AUTOSAR XML (schema 321)
standard types defined: Boolean, UInt16, UInt8, Float
package /ComponentType
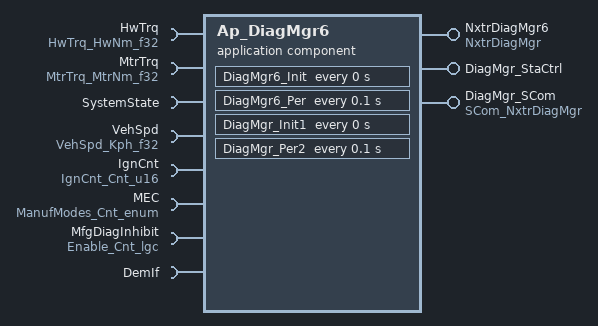
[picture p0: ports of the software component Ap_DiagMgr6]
  application software component type Ap_DiagMgr6
    provide port NxtrDiagMgr6: provided-interface=NxtrDiagMgr
      provided-com-specs:
        operation=GetNTCFailed, queue-length=1
        operation=GetNTCActive, queue-length=1
        operation=GetNTCStatus, queue-length=1
        operation=SetNTCStatus, queue-length=1
    8 x require port:
      HwTrq: unqueued-receiver-com-spec{data-element=HwNm_f32, handle-invalid=DONT-INVALIDATE, init-value=D_ZERO_ULS_F32}, required-interface=HwTrq_HwNm_f32
      MtrTrq: unqueued-receiver-com-spec{data-element=MtrNm_f32, init-value=D_ZERO_ULS_F32}, required-interface=MtrTrq_MtrNm_f32
      SystemState: required-interface=SystemState
      VehSpd: unqueued-receiver-com-spec{data-element=Kph_f32, handle-invalid=DONT-INVALIDATE, init-value=D_ZERO_ULS_F32}, required-interface=VehSpd_Kph_f32
      IgnCnt: unqueued-receiver-com-spec{data-element=Cnt_u16, init-value=D_ZERO_CNT_U16}, required-interface=IgnCnt_Cnt_u16
      MEC: unqueued-receiver-com-spec{data-element=Cnt_enum, handle-invalid=DONT-INVALIDATE, init-value=D_MANUFMODEINIT_CNT_ENUM}, required-interface=ManufModes_Cnt_enum
      MfgDiagInhibit: unqueued-receiver-com-spec{data-element=Enable_Cnt_lgc/Cnt_lgc, handle-invalid=DONT-INVALIDATE, init-value=D_FALSE_CNT_LGC}, required-interface=Enable_Cnt_lgc
      DemIf: required-com-specs=[DemShutdown, RestartDem, SetEventStatus, SetOperationCycleState], required-interface=DemIf
    provide port DiagMgr_StaCtrl: server-com-spec=Shutdown, provided-interface=DiagMgr_StaCtrl
    provide port DiagMgr_SCom: provided-interface=SCom_NxtrDiagMgr
      provided-com-specs:
        operation=GetNTCInfo, queue-length=1
        operation=ReadStrgArray, queue-length=1
        operation=ResetNTCStatus, queue-length=1
        operation=ClearBlackBox, queue-length=1
        operation=ClearLatchCounters, queue-length=1
  internal behavior Ap_DiagMgr6_InternalBehavior: component=Ap_DiagMgr6
    timing event DiagMgr6_Init_InitEvent: start-on-event=DiagMgr6_Init, period=0
    timing event TMT_DiagMgr6_Per: start-on-event=DiagMgr6_Per, period=0.1
    mode switch event MST_DiagMgr6_Trns_0: start-on-event=DiagMgr6_Trns, activation=EXIT, mode=SystemState.Mode.OFF
    timing event DiagMgr_Init1_InitEvent: start-on-event=DiagMgr_Init1, period=0
    timing event TMT_DiagMgr_Per2: mode-dependency=dependent-on-mode=SystemState.Mode.OFF, start-on-event=DiagMgr_Per2, period=0.1
    6 x operation invoked event:
      OIT_DiagMgr_SCom_GetNTCInfo_DiagMgr_SCom_GetInfo: start-on-event=DiagMgr_SCom_GetNTCInfo, operation=DiagMgr_SCom.GetNTCInfo
      OIT_DiagMgr_StaCtrl_Shutdown_DiagMgr_StaCtrl_Shutdown: start-on-event=DiagMgr_StaCtrl_Shutdown, operation=DiagMgr_StaCtrl.Shutdown
      OIT_DiagMgr_SCom_ReadStrgArray_DiagMgr_SCom_ReadStrgArray: start-on-event=DiagMgr_SCom_ReadStrgArray, operation=DiagMgr_SCom.ReadStrgArray
      OIT_DiagMgr_SCom_ReadStrgArray_DiagMgr_SCom_ResetNTCStatus: start-on-event=DiagMgr_SCom_ResetNTCStatus, operation=DiagMgr_SCom.ResetNTCStatus
      OIT_DiagMgr_SCom_ReadStrgArray_DiagMgr_SCom_ClearBlackBox: start-on-event=DiagMgr_SCom_ClearBlackBox, operation=DiagMgr_SCom.ClearBlackBox
      OIT_DiagMgr_SCom_ReadStrgArray_DiagMgr_SCom_ClearLatchCounters: start-on-event=DiagMgr_SCom_ClearLatchCounters, operation=DiagMgr_SCom.ClearLatchCounters
    mode switch event MST_DiagMgr_Trns1_0: start-on-event=DiagMgr_Trns1, activation=EXIT, mode=SystemState.Mode.OFF
    4 x operation invoked event:
      OIT_NxtrDiagMgr6_GetNTCFailed_NxtrDiagMgr6_GetNTCFailed: start-on-event=NxtrDiagMgr6_GetNTCFailed, operation=NxtrDiagMgr6.GetNTCFailed
      OIT_NxtrDiagMgr6_GetNTCActive_NxtrDiagMgr6_GetNTCActive: start-on-event=NxtrDiagMgr6_GetNTCActive, operation=NxtrDiagMgr6.GetNTCActive
      OIT_NxtrDiagMgr6_GetNTCStatus_NxtrDiagMgr6_GetNTCStatus: start-on-event=NxtrDiagMgr6_GetNTCStatus, operation=NxtrDiagMgr6.GetNTCStatus
      OIT_NxtrDiagMgr6_SetNTCStatus_NxtrDiagMgr6_SetNTCStatus: start-on-event=NxtrDiagMgr6_SetNTCStatus, operation=NxtrDiagMgr6.SetNTCStatus
    port-api-options:
      enable-take-address=false, indirect-api=false, port=NxtrDiagMgr6
      enable-take-address=false, indirect-api=false, port=Ap_DiagMgr6/MEC
      enable-take-address=false, indirect-api=false, port=Ap_DiagMgr6/MfgDiagInhibit
      enable-take-address=false, indirect-api=false, port=DemIf
      enable-take-address=false, indirect-api=false, port=DiagMgr_SCom
      enable-take-address=false, indirect-api=false, port=DemIf
    16 x runnable:
      NxtrDiagMgr6_GetNTCFailed: can-be-invoked-concurrently=true
      NxtrDiagMgr6_GetNTCActive: can-be-invoked-concurrently=true
      NxtrDiagMgr6_GetNTCStatus: can-be-invoked-concurrently=true
      NxtrDiagMgr6_SetNTCStatus: can-be-invoked-concurrently=true
        6 x data receive point:
          REC_MEC_Cnt_enum: data-element=MEC.Cnt_enum
          REC_MfgDiagInhibit_Cnt_lgc: data-element=MfgDiagInhibit.Cnt_lgc
          REC_HwTrq_HwNm_f32: data-element=HwTrq.HwNm_f32
          REC_MtrTrq_MtrNm_f32: data-element=MtrTrq.MtrNm_f32
          REC_IgnCnt_Cnt_u16: data-element=IgnCnt.Cnt_u16
          REC_VehSpd_Kph_f32: data-element=VehSpd.Kph_f32
      DiagMgr6_Init
        sync call SC_DemIf_SetOperationCycleState: operation=DemIf.SetOperationCycleState, timeout=0
      DiagMgr_StaCtrl_Shutdown
        sync call SC_DemIf_DemShutdown: operation=DemIf.DemShutdown, timeout=0
      DiagMgr6_Per
      DiagMgr6_Trns
      DiagMgr_Init1
      DiagMgr_Per2
        sync call SC_DemIf_SetEventStatus: operation=DemIf.SetEventStatus, timeout=0
      DiagMgr_Trns1
        sync call SC_DemIf_RestartDem: operation=DemIf.RestartDem, timeout=0
        sync call SC_DemIf_SetOperationCycleState: operation=DemIf.SetOperationCycleState, timeout=0
      DiagMgr_SCom_GetNTCInfo
      DiagMgr_SCom_ReadStrgArray
      DiagMgr_SCom_ResetNTCStatus
      DiagMgr_SCom_ClearBlackBox
      DiagMgr_SCom_ClearLatchCounters
  swc implementation DiagMgr6_Implementation: behavior=Ap_DiagMgr6_InternalBehavior
    code-descriptors:
      code Code: type=SRC
package /ComponentType
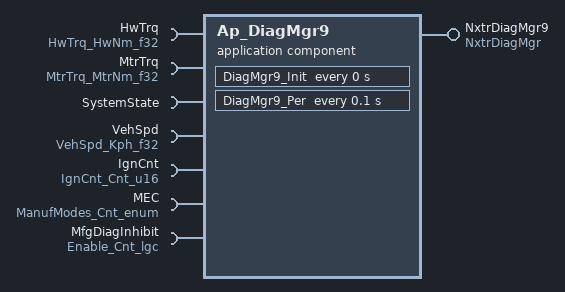
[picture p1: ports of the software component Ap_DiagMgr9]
  application software component type Ap_DiagMgr9
    provide port NxtrDiagMgr9: provided-interface=NxtrDiagMgr
      provided-com-specs:
        operation=GetNTCFailed, queue-length=1
        operation=GetNTCActive, queue-length=1
        operation=GetNTCStatus, queue-length=1
        operation=SetNTCStatus, queue-length=1
    7 x require port:
      HwTrq: unqueued-receiver-com-spec{data-element=HwNm_f32, handle-invalid=DONT-INVALIDATE, init-value=D_ZERO_ULS_F32}, required-interface=HwTrq_HwNm_f32
      MtrTrq: unqueued-receiver-com-spec{data-element=MtrNm_f32, init-value=D_ZERO_ULS_F32}, required-interface=MtrTrq_MtrNm_f32
      SystemState: required-interface=SystemState
      VehSpd: unqueued-receiver-com-spec{data-element=Kph_f32, handle-invalid=DONT-INVALIDATE, init-value=D_ZERO_ULS_F32}, required-interface=VehSpd_Kph_f32
      IgnCnt: unqueued-receiver-com-spec{data-element=Cnt_u16, init-value=D_ZERO_CNT_U16}, required-interface=IgnCnt_Cnt_u16
      MEC: unqueued-receiver-com-spec{data-element=Cnt_enum, handle-invalid=DONT-INVALIDATE, init-value=D_MANUFMODEINIT_CNT_ENUM}, required-interface=ManufModes_Cnt_enum
      MfgDiagInhibit: unqueued-receiver-com-spec{data-element=Enable_Cnt_lgc/Cnt_lgc, handle-invalid=DONT-INVALIDATE, init-value=D_FALSE_CNT_LGC}, required-interface=Enable_Cnt_lgc
  internal behavior Ap_DiagMgr9_InternalBehavior: component=Ap_DiagMgr9
    timing event DiagMgr9_Init_InitEvent: start-on-event=DiagMgr9_Init, period=0
    timing event TMT_DiagMgr9_Per: start-on-event=DiagMgr9_Per, period=0.1
    mode switch event MST_DiagMgr9_Trns_0: start-on-event=DiagMgr9_Trns, activation=EXIT, mode=SystemState.Mode.OFF
    4 x operation invoked event:
      OIT_NxtrDiagMgr9_GetNTCFailed_NxtrDiagMgr9_GetNTCFailed: start-on-event=NxtrDiagMgr9_GetNTCFailed, operation=NxtrDiagMgr9.GetNTCFailed
      OIT_NxtrDiagMgr9_GetNTCActive_NxtrDiagMgr9_GetNTCActive: start-on-event=NxtrDiagMgr9_GetNTCActive, operation=NxtrDiagMgr9.GetNTCActive
      OIT_NxtrDiagMgr9_GetNTCStatus_NxtrDiagMgr9_GetNTCStatus: start-on-event=NxtrDiagMgr9_GetNTCStatus, operation=NxtrDiagMgr9.GetNTCStatus
      OIT_NxtrDiagMgr9_SetNTCStatus_NxtrDiagMgr9_SetNTCStatus: start-on-event=NxtrDiagMgr9_SetNTCStatus, operation=NxtrDiagMgr9.SetNTCStatus
    port-api-options:
      enable-take-address=false, indirect-api=false, port=NxtrDiagMgr9
      enable-take-address=false, indirect-api=false, port=Ap_DiagMgr9/MEC
      enable-take-address=false, indirect-api=false, port=Ap_DiagMgr9/MfgDiagInhibit
    7 x runnable:
      NxtrDiagMgr9_GetNTCFailed: can-be-invoked-concurrently=true
      NxtrDiagMgr9_GetNTCActive: can-be-invoked-concurrently=true
      NxtrDiagMgr9_GetNTCStatus: can-be-invoked-concurrently=true
      NxtrDiagMgr9_SetNTCStatus: can-be-invoked-concurrently=true
        6 x data receive point:
          REC_MEC_Cnt_enum: data-element=MEC.Cnt_enum
          REC_MfgDiagInhibit_Cnt_lgc: data-element=MfgDiagInhibit.Cnt_lgc
          REC_HwTrq_HwNm_f32: data-element=HwTrq.HwNm_f32
          REC_MtrTrq_MtrNm_f32: data-element=MtrTrq.MtrNm_f32
          REC_IgnCnt_Cnt_u16: data-element=IgnCnt.Cnt_u16
          REC_VehSpd_Kph_f32: data-element=VehSpd.Kph_f32
      DiagMgr9_Init
      DiagMgr9_Per
      DiagMgr9_Trns
  swc implementation DiagMgr9_Implementation: behavior=Ap_DiagMgr9_InternalBehavior
    code-descriptors:
      code Code: type=SRC
package /ComponentType
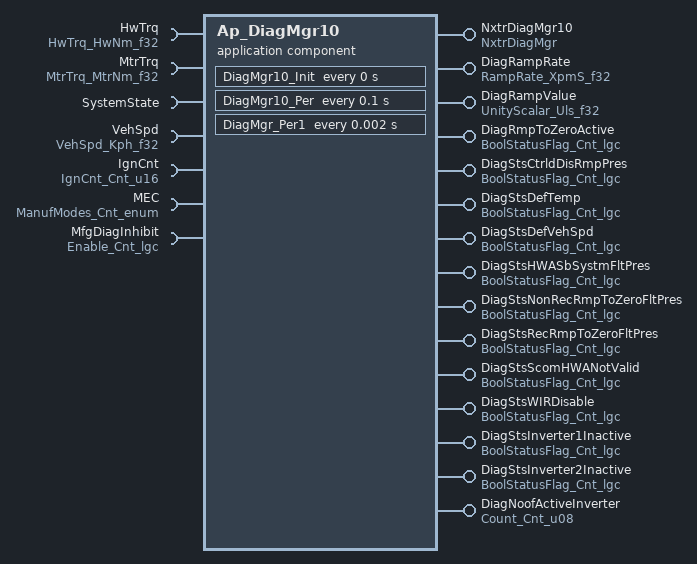
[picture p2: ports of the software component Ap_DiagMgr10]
  application software component type Ap_DiagMgr10
    provide port NxtrDiagMgr10: provided-interface=NxtrDiagMgr
      provided-com-specs:
        operation=GetNTCFailed, queue-length=1
        operation=GetNTCActive, queue-length=1
        operation=GetNTCStatus, queue-length=1
        operation=SetNTCStatus, queue-length=1
    7 x require port:
      HwTrq: unqueued-receiver-com-spec{data-element=HwNm_f32, handle-invalid=DONT-INVALIDATE, init-value=D_ZERO_ULS_F32}, required-interface=HwTrq_HwNm_f32
      MtrTrq: unqueued-receiver-com-spec{data-element=MtrNm_f32, init-value=D_ZERO_ULS_F32}, required-interface=MtrTrq_MtrNm_f32
      SystemState: required-interface=SystemState
      VehSpd: unqueued-receiver-com-spec{data-element=Kph_f32, handle-invalid=DONT-INVALIDATE, init-value=D_ZERO_ULS_F32}, required-interface=VehSpd_Kph_f32
      IgnCnt: unqueued-receiver-com-spec{data-element=Cnt_u16, init-value=D_ZERO_CNT_U16}, required-interface=IgnCnt_Cnt_u16
      MEC: unqueued-receiver-com-spec{data-element=Cnt_enum, handle-invalid=DONT-INVALIDATE, init-value=D_MANUFMODEINIT_CNT_ENUM}, required-interface=ManufModes_Cnt_enum
      MfgDiagInhibit: unqueued-receiver-com-spec{data-element=Enable_Cnt_lgc/Cnt_lgc, handle-invalid=DONT-INVALIDATE, init-value=D_FALSE_CNT_LGC}, required-interface=Enable_Cnt_lgc
    14 x provide port:
      DiagRampRate: unqueued-sender-com-spec{data-element=XpmS_f32, can-invalidate=false, init-value=D_ZERO_ULS_F32}, provided-interface=RampRate_XpmS_f32
      DiagRampValue: unqueued-sender-com-spec{data-element=Uls_f32, can-invalidate=false, init-value=D_ZERO_ULS_F32}, provided-interface=UnityScalar_Uls_f32
      DiagRmpToZeroActive: unqueued-sender-com-spec{data-element=BoolStatusFlag_Cnt_lgc/Cnt_lgc, can-invalidate=false, init-value=D_FALSE_CNT_LGC}, provided-interface=BoolStatusFlag_Cnt_lgc
      DiagStsCtrldDisRmpPres: unqueued-sender-com-spec{data-element=BoolStatusFlag_Cnt_lgc/Cnt_lgc, can-invalidate=false, init-value=D_FALSE_CNT_LGC}, provided-interface=BoolStatusFlag_Cnt_lgc
      DiagStsDefTemp: unqueued-sender-com-spec{data-element=BoolStatusFlag_Cnt_lgc/Cnt_lgc, can-invalidate=false, init-value=D_FALSE_CNT_LGC}, provided-interface=BoolStatusFlag_Cnt_lgc
      DiagStsDefVehSpd: unqueued-sender-com-spec{data-element=BoolStatusFlag_Cnt_lgc/Cnt_lgc, can-invalidate=false, init-value=D_FALSE_CNT_LGC}, provided-interface=BoolStatusFlag_Cnt_lgc
      DiagStsHWASbSystmFltPres: unqueued-sender-com-spec{data-element=BoolStatusFlag_Cnt_lgc/Cnt_lgc, can-invalidate=false, init-value=D_FALSE_CNT_LGC}, provided-interface=BoolStatusFlag_Cnt_lgc
      DiagStsNonRecRmpToZeroFltPres: unqueued-sender-com-spec{data-element=BoolStatusFlag_Cnt_lgc/Cnt_lgc, can-invalidate=false, init-value=D_FALSE_CNT_LGC}, provided-interface=BoolStatusFlag_Cnt_lgc
      DiagStsRecRmpToZeroFltPres: unqueued-sender-com-spec{data-element=BoolStatusFlag_Cnt_lgc/Cnt_lgc, can-invalidate=false, init-value=D_FALSE_CNT_LGC}, provided-interface=BoolStatusFlag_Cnt_lgc
      DiagStsScomHWANotValid: unqueued-sender-com-spec{data-element=BoolStatusFlag_Cnt_lgc/Cnt_lgc, can-invalidate=false, init-value=D_FALSE_CNT_LGC}, provided-interface=BoolStatusFlag_Cnt_lgc
      DiagStsWIRDisable: unqueued-sender-com-spec{data-element=BoolStatusFlag_Cnt_lgc/Cnt_lgc, can-invalidate=false, init-value=D_FALSE_CNT_LGC}, provided-interface=BoolStatusFlag_Cnt_lgc
      DiagStsInverter1Inactive: unqueued-sender-com-spec{data-element=BoolStatusFlag_Cnt_lgc/Cnt_lgc, can-invalidate=false, init-value=D_FALSE_CNT_LGC}, provided-interface=BoolStatusFlag_Cnt_lgc
      DiagStsInverter2Inactive: unqueued-sender-com-spec{data-element=BoolStatusFlag_Cnt_lgc/Cnt_lgc, can-invalidate=false, init-value=D_FALSE_CNT_LGC}, provided-interface=BoolStatusFlag_Cnt_lgc
      DiagNoofActiveInverter: unqueued-sender-com-spec{data-element=Cnt_u08, can-invalidate=false, init-value=D_TWO_CNT_U08}, provided-interface=Count_Cnt_u08
  internal behavior Ap_DiagMgr10_InternalBehavior: component=Ap_DiagMgr10
    timing event DiagMgr10_Init_InitEvent: start-on-event=DiagMgr10_Init, period=0
    timing event TMT_DiagMgr10_Per: start-on-event=DiagMgr10_Per, period=0.1
    mode switch event MST_DiagMgr10_Trns_0: start-on-event=DiagMgr10_Trns, activation=EXIT, mode=SystemState.Mode.OFF
    timing event TMT_DiagMgr_Per1: start-on-event=DiagMgr_Per1, period=0.002
    4 x operation invoked event:
      OIT_NxtrDiagMgr10_GetNTCFailed_NxtrDiagMgr10_GetNTCFailed: start-on-event=NxtrDiagMgr10_GetNTCFailed, operation=NxtrDiagMgr10.GetNTCFailed
      OIT_NxtrDiagMgr10_GetNTCActive_NxtrDiagMgr10_GetNTCActive: start-on-event=NxtrDiagMgr10_GetNTCActive, operation=NxtrDiagMgr10.GetNTCActive
      OIT_NxtrDiagMgr10_GetNTCStatus_NxtrDiagMgr10_GetNTCStatus: start-on-event=NxtrDiagMgr10_GetNTCStatus, operation=NxtrDiagMgr10.GetNTCStatus
      OIT_NxtrDiagMgr10_SetNTCStatus_NxtrDiagMgr10_SetNTCStatus: start-on-event=NxtrDiagMgr10_SetNTCStatus, operation=NxtrDiagMgr10.SetNTCStatus
    port-api-options:
      enable-take-address=false, indirect-api=false, port=NxtrDiagMgr10
      enable-take-address=false, indirect-api=false, port=Ap_DiagMgr10/MEC
      enable-take-address=false, indirect-api=false, port=Ap_DiagMgr10/MfgDiagInhibit
      enable-take-address=false, indirect-api=false, port=DiagRampRate
      enable-take-address=false, indirect-api=false, port=DiagRampValue
      enable-take-address=false, indirect-api=false, port=DiagRmpToZeroActive
      enable-take-address=false, indirect-api=false, port=DiagStsCtrldDisRmpPres
      enable-take-address=false, indirect-api=false, port=DiagStsDefTemp
      enable-take-address=false, indirect-api=false, port=DiagStsDefVehSpd
      enable-take-address=false, indirect-api=false, port=DiagStsHWASbSystmFltPres
      enable-take-address=false, indirect-api=false, port=DiagStsNonRecRmpToZeroFltPres
      enable-take-address=false, indirect-api=false, port=DiagStsRecRmpToZeroFltPres
      enable-take-address=false, indirect-api=false, port=DiagStsScomHWANotValid
      enable-take-address=false, indirect-api=false, port=DiagStsWIRDisable
      enable-take-address=false, indirect-api=false, port=DiagStsInverter1Inactive
      enable-take-address=false, indirect-api=false, port=DiagStsInverter2Inactive
      enable-take-address=false, indirect-api=false, port=DiagNoofActiveInverter
      enable-take-address=false, indirect-api=false, port=Ap_DiagMgr10/SystemState
    8 x runnable:
      NxtrDiagMgr10_GetNTCFailed: can-be-invoked-concurrently=true
      NxtrDiagMgr10_GetNTCActive: can-be-invoked-concurrently=true
      NxtrDiagMgr10_GetNTCStatus: can-be-invoked-concurrently=true
      NxtrDiagMgr10_SetNTCStatus: can-be-invoked-concurrently=true
        6 x data receive point:
          REC_MEC_Cnt_enum: data-element=MEC.Cnt_enum
          REC_MfgDiagInhibit_Cnt_lgc: data-element=MfgDiagInhibit.Cnt_lgc
          REC_HwTrq_HwNm_f32: data-element=HwTrq.HwNm_f32
          REC_MtrTrq_MtrNm_f32: data-element=MtrTrq.MtrNm_f32
          REC_IgnCnt_Cnt_u16: data-element=IgnCnt.Cnt_u16
          REC_VehSpd_Kph_f32: data-element=VehSpd.Kph_f32
      DiagMgr10_Init
      DiagMgr10_Per
      DiagMgr10_Trns
      DiagMgr_Per1
        14 x data send point:
          SEND_DiagRampRate_XpmS_f32: data-element=DiagRampRate.XpmS_f32
          SEND_DiagRampValue_Uls_f32: data-element=DiagRampValue.Uls_f32
          SEND_DiagRmpToZeroActive_Cnt_lgc: data-element=DiagRmpToZeroActive.Cnt_lgc
          SEND_DiagStsCtrldDisRmpPres_Cnt_lgc: data-element=DiagStsCtrldDisRmpPres.Cnt_lgc
          SEND_DiagStsDefTemp_Cnt_lgc: data-element=DiagStsDefTemp.Cnt_lgc
          SEND_DiagStsDefVehSpd_Cnt_lgc: data-element=DiagStsDefVehSpd.Cnt_lgc
          SEND_DiagStsHWASbSystmFltPres_Cnt_lgc: data-element=DiagStsHWASbSystmFltPres.Cnt_lgc
          SEND_DiagStsNonRecRmpToZeroFltPres_Cnt_lgc: data-element=DiagStsNonRecRmpToZeroFltPres.Cnt_lgc
          SEND_DiagStsRecRmpToZeroFltPres_Cnt_lgc: data-element=DiagStsRecRmpToZeroFltPres.Cnt_lgc
          SEND_DiagStsScomHWANotValid_Cnt_lgc: data-element=DiagStsScomHWANotValid.Cnt_lgc
          SEND_DiagStsWIRDisable_Cnt_lgc: data-element=DiagStsWIRDisable.Cnt_lgc
          SEND_DiagStsInverter1Inactive_Cnt_lgc: data-element=DiagStsInverter1Inactive.Cnt_lgc
          SEND_DiagStsInverter2Inactive_Cnt_lgc: data-element=DiagStsInverter2Inactive.Cnt_lgc
          SEND_DiagNoofActiveInverter_Cnt_u08: data-element=DiagNoofActiveInverter.Cnt_u08
  swc implementation DiagMgr10_Implementation: behavior=Ap_DiagMgr10_InternalBehavior
    code-descriptors:
      code Code: type=SRC
package /ComponentType
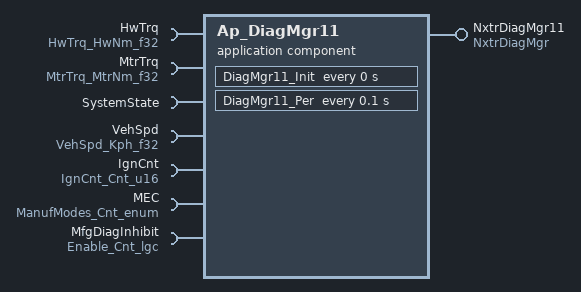
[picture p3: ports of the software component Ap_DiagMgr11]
  application software component type Ap_DiagMgr11
    provide port NxtrDiagMgr11: provided-interface=NxtrDiagMgr
      provided-com-specs:
        operation=GetNTCFailed, queue-length=1
        operation=GetNTCActive, queue-length=1
        operation=GetNTCStatus, queue-length=1
        operation=SetNTCStatus, queue-length=1
    7 x require port:
      HwTrq: unqueued-receiver-com-spec{data-element=HwNm_f32, handle-invalid=DONT-INVALIDATE, init-value=D_ZERO_ULS_F32}, required-interface=HwTrq_HwNm_f32
      MtrTrq: unqueued-receiver-com-spec{data-element=MtrNm_f32, init-value=D_ZERO_ULS_F32}, required-interface=MtrTrq_MtrNm_f32
      SystemState: required-interface=SystemState
      VehSpd: unqueued-receiver-com-spec{data-element=Kph_f32, handle-invalid=DONT-INVALIDATE, init-value=D_ZERO_ULS_F32}, required-interface=VehSpd_Kph_f32
      IgnCnt: unqueued-receiver-com-spec{data-element=Cnt_u16, init-value=D_ZERO_CNT_U16}, required-interface=IgnCnt_Cnt_u16
      MEC: unqueued-receiver-com-spec{data-element=Cnt_enum, handle-invalid=DONT-INVALIDATE, init-value=D_MANUFMODEINIT_CNT_ENUM}, required-interface=ManufModes_Cnt_enum
      MfgDiagInhibit: unqueued-receiver-com-spec{data-element=Enable_Cnt_lgc/Cnt_lgc, handle-invalid=DONT-INVALIDATE, init-value=D_FALSE_CNT_LGC}, required-interface=Enable_Cnt_lgc
  internal behavior Ap_DiagMgr11_InternalBehavior: component=Ap_DiagMgr11
    timing event DiagMgr11_Init_InitEvent: start-on-event=DiagMgr11_Init, period=0
    timing event TMT_DiagMgr11_Per: start-on-event=DiagMgr11_Per, period=0.1
    mode switch event MST_DiagMgr11_Trns_0: start-on-event=DiagMgr11_Trns, activation=EXIT, mode=SystemState.Mode.OFF
    4 x operation invoked event:
      OIT_NxtrDiagMgr11_GetNTCFailed_NxtrDiagMgr11_GetNTCFailed: start-on-event=NxtrDiagMgr11_GetNTCFailed, operation=NxtrDiagMgr11.GetNTCFailed
      OIT_NxtrDiagMgr11_GetNTCActive_NxtrDiagMgr11_GetNTCActive: start-on-event=NxtrDiagMgr11_GetNTCActive, operation=NxtrDiagMgr11.GetNTCActive
      OIT_NxtrDiagMgr11_GetNTCStatus_NxtrDiagMgr11_GetNTCStatus: start-on-event=NxtrDiagMgr11_GetNTCStatus, operation=NxtrDiagMgr11.GetNTCStatus
      OIT_NxtrDiagMgr11_SetNTCStatus_NxtrDiagMgr11_SetNTCStatus: start-on-event=NxtrDiagMgr11_SetNTCStatus, operation=NxtrDiagMgr11.SetNTCStatus
    port-api-options:
      enable-take-address=false, indirect-api=false, port=NxtrDiagMgr11
      enable-take-address=false, indirect-api=false, port=Ap_DiagMgr11/MEC
      enable-take-address=false, indirect-api=false, port=Ap_DiagMgr11/MfgDiagInhibit
    7 x runnable:
      NxtrDiagMgr11_GetNTCFailed: can-be-invoked-concurrently=true
      NxtrDiagMgr11_GetNTCActive: can-be-invoked-concurrently=true
      NxtrDiagMgr11_GetNTCStatus: can-be-invoked-concurrently=true
      NxtrDiagMgr11_SetNTCStatus: can-be-invoked-concurrently=true
        6 x data receive point:
          REC_MEC_Cnt_enum: data-element=MEC.Cnt_enum
          REC_MfgDiagInhibit_Cnt_lgc: data-element=MfgDiagInhibit.Cnt_lgc
          REC_HwTrq_HwNm_f32: data-element=HwTrq.HwNm_f32
          REC_MtrTrq_MtrNm_f32: data-element=MtrTrq.MtrNm_f32
          REC_IgnCnt_Cnt_u16: data-element=IgnCnt.Cnt_u16
          REC_VehSpd_Kph_f32: data-element=VehSpd.Kph_f32
      DiagMgr11_Init
      DiagMgr11_Per
      DiagMgr11_Trns
  swc implementation DiagMgr11_Implementation: behavior=Ap_DiagMgr11_InternalBehavior
    code-descriptors:
      code Code: type=SRC
package /Constant
  5 x constant specification:
    D_FALSE_CNT_LGC
      value:
        boolean literal D_FALSE_CNT_LGC: type=Boolean, value=false
    D_TWO_CNT_U08
      value:
        integer literal D_TWO_CNT_U08: type=UInt8, value=2
    D_MANUFMODEINIT_CNT_ENUM
      value:
        integer literal D_MANUFMODEINIT_CNT_ENUM: type=ManufModeType, value=0
    D_ZERO_ULS_F32
      value:
        real literal D_ZERO_ULS_F32: type=Float, value=0
    D_ZERO_CNT_U16
      value:
        real literal D_ZERO_CNT_U16: type=UInt16, value=0
package /DataType
  5 x integer type:
    ManufModeType: compu {0=ProductionMode, 1=ManufacturingMode, 2=EngineeringMode}, lower-limit=0, upper-limit=2
    NTCNumber: lower-limit=0, upper-limit=511
    NxtrDiagMgrStatus: compu {0=NTC_STATUS_PASSED, 1=NTC_STATUS_FAILED, 2=NTC_STATUS_PREPASSED, 3=NTC_STATUS_PREFAILED}, lower-limit=0, upper-limit=255
    NxtrOpCycle: compu {0=NxtrDefaultOpCycle}, lower-limit=0, upper-limit=0
    NxtrOpCycleState: compu {1=NXTR_CYCLE_STATE_START, 2=NXTR_CYCLE_STATE_END}, lower-limit=1, upper-limit=2
package /ModeDclrGroup
  mode declaration group StaMd_Mode: initial-mode=WARMINIT  # EPS System State mode declaration
    4 x mode:
      DISABLE
      OFF
      OPERATE
      WARMINIT
package /PortInterface
  5 x client server interface:
    DiagMgr_StaCtrl
      operation Shutdown
    DemIf
      4 x operation:
        DemShutdown
        RestartDem
        SetEventStatus: possible-error=DemIf/E_NOT_OK
          arg EventId: type=UInt8, direction=IN
          arg EventStatus: type=NxtrDiagMgrStatus, direction=IN
        SetOperationCycleState
          arg NxtrOperationCycleId: type=NxtrOpCycle, direction=IN
          arg NxtrCycleState: type=NxtrOpCycleState, direction=IN
      error E_NOT_OK: error-code=1
    NxtrDiagMgr
      4 x operation, all with possible-error=NxtrDiagMgr/E_NOT_OK:
        GetNTCFailed
          arg NTC_Cnt_T_enum: type=NTCNumber, direction=IN
          arg NTCFailed_Ptr_T_lgc: type=Boolean, direction=OUT
        GetNTCActive
          arg NTC_Cnt_T_enum: type=NTCNumber, direction=IN
          arg NTCActive_Ptr_T_lgc: type=Boolean, direction=OUT
        GetNTCStatus
          arg NTC_Cnt_T_enum: type=NTCNumber, direction=IN
          arg Status_Ptr_T_u08: type=UInt8, direction=OUT
        SetNTCStatus
          arg NTC_Cnt_T_enum: type=NTCNumber, direction=IN
          arg Param_Cnt_T_u08: type=UInt8, direction=IN
          arg Status_Cnt_T_enum: type=NxtrDiagMgrStatus, direction=IN
      error E_NOT_OK: error-code=1
    SCom_NxtrDiagMgr
      5 x operation:
        GetNTCInfo
          4 x arg:
            NTC_Cnt_T_enum: type=NTCNumber, direction=IN
            Param_Ptr_T_u08: type=UInt8, direction=OUT
            Status_Ptr_T_u08: type=UInt8, direction=OUT
            AgingCounter_Ptr_T_u08: type=UInt8, direction=OUT
        ResetNTCStatus
        ReadStrgArray
        ClearBlackBox
        ClearLatchCounters
    WdgM_CheckpointReached: is-service=true
      operation CheckpointReached: possible-error=WdgM_CheckpointReached/E_NOT_OK  # Indicates to the Watchdog Manager that a Checkpoint within a Supervised Entity has been reached.
      error E_NOT_OK: error-code=1
  11 x sender receiver interface:
    HwTrq_HwNm_f32
      data HwNm_f32: sw-calibration-access=READ-ONLY, type=Float
    MtrTrq_MtrNm_f32
      data MtrNm_f32: sw-calibration-access=READ-ONLY, type=Float
    IgnCnt_Cnt_u16
      data Cnt_u16: sw-calibration-access=READ-ONLY, type=UInt16
    ManufModes_Cnt_enum
      data Cnt_enum: sw-calibration-access=READ-ONLY, type=ManufModeType
    RampRate_XpmS_f32
      data XpmS_f32: sw-calibration-access=READ-ONLY, type=Float
    SystemState
      mode declaration group prototype Mode: type=StaMd_Mode
    VehSpd_Kph_f32
      data Kph_f32: sw-calibration-access=READ-ONLY, type=Float
    BoolStatusFlag_Cnt_lgc
      data Cnt_lgc: sw-calibration-access=READ-ONLY, type=Boolean
    Count_Cnt_u08
      data Cnt_u08: sw-calibration-access=READ-ONLY, type=UInt8
    Enable_Cnt_lgc
      data Cnt_lgc: sw-calibration-access=READ-ONLY, type=Boolean
    UnityScalar_Uls_f32
      data Uls_f32: sw-calibration-access=READ-ONLY, type=Float
